# AS32x601 register map
File version: 1.0
CPU: RISC-V, little endian
Registers are 32-bit, read-write, reset 0x0 unless marked. A register's access mark holds for its fields unless they carry their own. Offsets are from the block's base; [hi:lo] are bit positions; {n}, {i} and the like mark numbered series.

## SMU — System Management Unit
Base 0x30006000
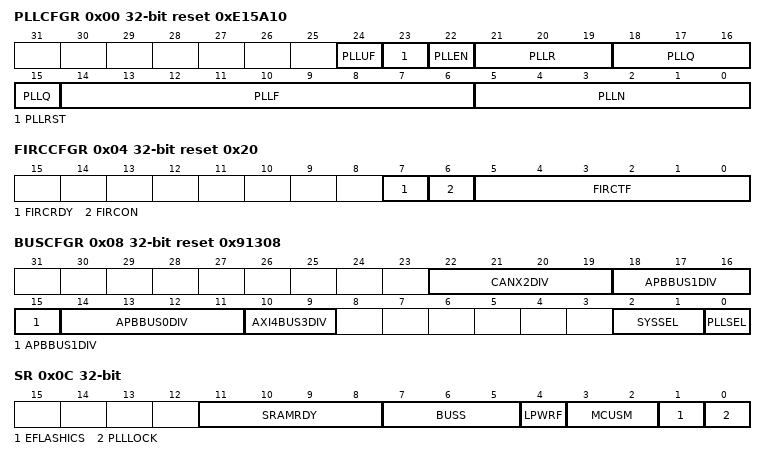
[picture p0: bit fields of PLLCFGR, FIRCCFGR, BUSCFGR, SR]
0x00 PLLCFGR reset 0xE15A10 — PLL divide and reset configuration registers
  [24] PLLUF — Update PLL frequency enable
  [23] PLLRST — PLL clock reset signal
  [22] PLLEN — PLL clock enable
  [21:19] PLLR — Output frequency division control signal of CLK_R [2:0]
  [18:15] PLLQ — Output frequency division control signal of CLK_Q [3:0]
  [14:6] PLLF — Feedback clock control signal [8:0]
  [5:0] PLLN — Input frequency division control signal [5:0]
0x04 FIRCCFGR reset 0x20 — Internal clock and reset configuration registers
  [7] FIRCRDY — FIRC oscillator preparation position
  [6] FIRCON — FIRC oscillator switch
  [5:0] FIRCTF — FIRC oscillator frequency adjustment [5:0]
0x08 BUSCFGR reset 0x91308 — BUS clock and reset configuration registers
  [22:19] CANX2DIV — CANX2 clock division ratio [3:0]
  [18:15] APBBUS1DIV — ApbBus1 clock division ratio [3:0]
  [14:11] APBBUS0DIV — ApbBus0 clock division ratio [3:0]
  [10:9] AXI4BUS3DIV — Axi4Bus3 clock division ratio [1:0]
  [2:1] SYSSEL — System clock selection [1:0]
  [0] PLLSEL — PLL clock selection
0x0C SR ro — SMU state registers
  [11:8] SRAMRDY — SRAM ready [3:0]
  [7:5] BUSS — Bus state [2:0]
  [4] LPWRF — Low power mode flag
  [3:2] MCUSM — MCU startup mode [1:0]
  [1] EFLASHICS — EFLASH initialization completion signal
  [0] PLLLOCK — PLL clock lock
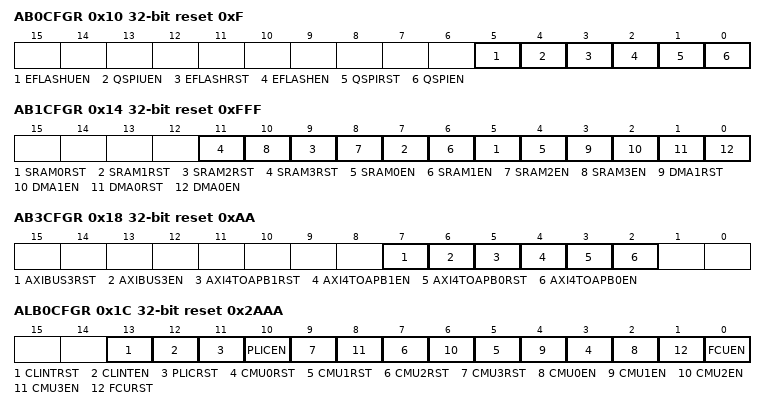
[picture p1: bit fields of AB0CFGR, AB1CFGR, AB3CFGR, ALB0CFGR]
0x10 AB0CFGR reset 0xF — AB0 bus clock and reset configuration register
  [5] EFLASHUEN — EFLASH clock update enable
  [4] QSPIUEN — QSPI Clock update Enable
  [3] EFLASHRST — EFLASH reset
  [2] EFLASHEN — EFLASH clock enable
  [1] QSPIRST — QSPI reset
  [0] QSPIEN — QSPI clock enable
0x14 AB1CFGR reset 0xFFF — AB1 bus clock and reset configuration register
  [2n+5] SRAM{n}RST (n=0..3) — SRAM{n} reset
  [2n+4] SRAM{n}EN (n=0..3) — SRAM{n} clock enable
  [3] DMA1RST — DMA1 reset
  [2] DMA1EN — DMA1 clock enable
  [1] DMA0RST — DMA0 reset
  [0] DMA0EN — DMA0 clock enable
0x18 AB3CFGR reset 0xAA — AB3 bus clock and reset configuration registers
  [7] AXIBUS3RST — AxiBux3 reset
  [6] AXIBUS3EN — AxiBux3 clock enable
  [5] AXI4TOAPB1RST — AXI4 to APB1 reset
  [4] AXI4TOAPB1EN — AXI4 to APB1 clock enable
  [3] AXI4TOAPB0RST — AXI4 to APB0 reset
  [2] AXI4TOAPB0EN — AXI4 to APB0 clock enable
0x1C ALB0CFGR reset 0x2AAA — ALB0 bus clock and reset configuration registers
  [13] CLINTRST — CLINT reset
  [12] CLINTEN — CLINT clock enable
  [11] PLICRST — PLIC reset
  [10] PLICEN — PLIC clock enable
  [2n+3] CMU{n}RST (n=0..3) — CMU{n} reset
  [2n+2] CMU{n}EN (n=0..3) — CMU{n} clock enable
  [1] FCURST — FCU reset
  [0] FCUEN — FCU clock enable
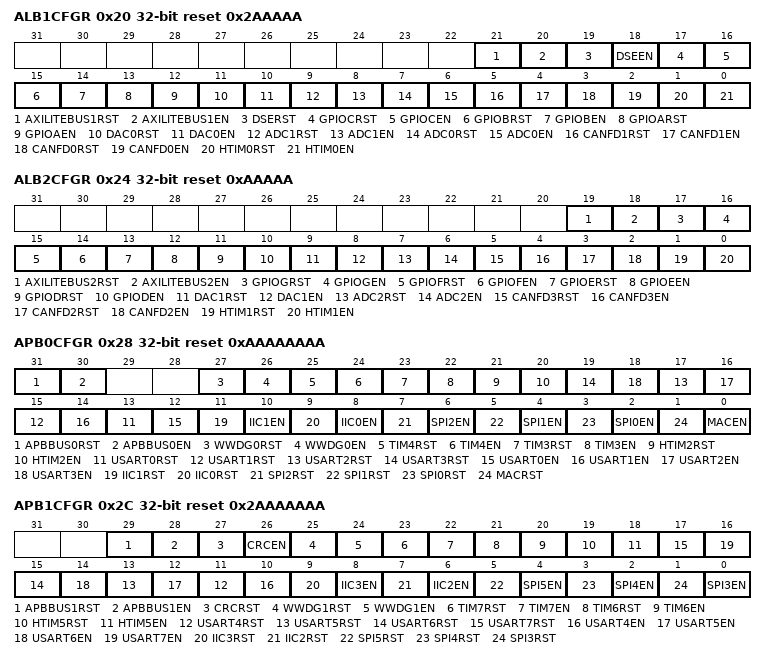
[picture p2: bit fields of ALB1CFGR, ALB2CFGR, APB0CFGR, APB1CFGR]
0x20 ALB1CFGR reset 0x2AAAAA — ALB1 bus clock and reset configuration registers
  [21] AXILITEBUS1RST — AXILiteBUS1 reset
  [20] AXILITEBUS1EN — AXILiteBUS1 clock enable
  [19] DSERST — DSE reset
  [18] DSEEN — DSE clock enable
  [17] GPIOCRST — GPIOC reset
  [16] GPIOCEN — GPIOC clock enable
  [15] GPIOBRST — GPIOB reset
  [14] GPIOBEN — GPIOB clock enable
  [13] GPIOARST — GPIOA reset
  [12] GPIOAEN — GPIOA clock enable
  [11] DAC0RST — DAC0 reset
  [10] DAC0EN — DAC0 clock enable
  [9] ADC1RST — ADC1 reset
  [8] ADC1EN — ADC1 clock enable
  [7] ADC0RST — ADC0 reset
  [6] ADC0EN — ADC0 clock enable
  [5] CANFD1RST — CANFD1 reset
  [4] CANFD1EN — CANFD1 clock enable
  [3] CANFD0RST — CANFD0 reset
  [2] CANFD0EN — CANFD0 clock enable
  [1] HTIM0RST — HTIM0 reset
  [0] HTIM0EN — HTIM0 clock enable
0x24 ALB2CFGR reset 0xAAAAA — ALB2 bus clock and reset configuration registers
  [19] AXILITEBUS2RST — AXILite Bus2 reset
  [18] AXILITEBUS2EN — AXILite Bus2 clock enable
  [17] GPIOGRST — GPIOG reset
  [16] GPIOGEN — GPIOG clock enable
  [15] GPIOFRST — GPIOF reset
  [14] GPIOFEN — GPIOF clock enable
  [13] GPIOERST — GPIOE reset
  [12] GPIOEEN — GPIOE clock enable
  [11] GPIODRST — GPIOD reset
  [10] GPIODEN — GPIOD clock enable
  [9] DAC1RST — DAC1 reset
  [8] DAC1EN — DAC1 clock enable
  [7] ADC2RST — ADC2 reset
  [6] ADC2EN — ADC2 clock enable
  [5] CANFD3RST — CANFD3 reset
  [4] CANFD3EN — CANFD3 clock enable
  [3] CANFD2RST — CANFD2 reset
  [2] CANFD2EN — CANFD2 clock enable
  [1] HTIM1RST — HTIM1 reset
  [0] HTIM1EN — HTIM1 clock enable
0x28 APB0CFGR reset 0xAAAAAAAA — APB0 bus clock and reset configuration registers
  [31] APBBUS0RST — APBBUS0 reset
  [30] APBBUS0EN — APBBUS0 clock enable
  [27] WWDG0RST — WWDG0 reset
  [26] WWDG0EN — WWDG0 clock enable
  [25] TIM4RST — TIM4 reset
  [24] TIM4EN — TIM4 clock enable
  [23] TIM3RST — TIM3 reset
  [22] TIM3EN — TIM3 clock enable
  [21] HTIM2RST — HTIM2 reset
  [20] HTIM2EN — HTIM2 clock enable
  [2n+13] USART{n}RST (n=0..3) — USART{n} reset
  [2n+12] USART{n}EN (n=0..3) — USART{n} clock enable
  [11] IIC1RST — IIC1 reset
  [10] IIC1EN — IIC1 clock enable
  [9] IIC0RST — IIC0 reset
  [8] IIC0EN — IIC0 clock enable
  [7] SPI2RST — SPI2 reset
  [6] SPI2EN — SPI2 clock enable
  [5] SPI1RST — SPI1 reset
  [4] SPI1EN — SPI1 clock enable
  [3] SPI0RST — SPI0 reset
  [2] SPI0EN — SPI0 clock enable
  [1] MACRST — MAC reset
  [0] MACEN — MAC clock enable
0x2C APB1CFGR reset 0x2AAAAAAA — APB1 bus clock and reset configuration registers
  [29] APBBUS1RST — APB1BUS1 reset
  [28] APBBUS1EN — APB1BUS1 clock enable
  [27] CRCRST — CRC reset
  [26] CRCEN — CRC clock enable
  [25] WWDG1RST — WWDG1 reset
  [24] WWDG1EN — WWDG1 clock enable
  [23] TIM7RST — TIM7 reset
  [22] TIM7EN — TIM7 clock enable
  [21] TIM6RST — TIM6 reset
  [20] TIM6EN — TIM6 clock enable
  [19] HTIM5RST — HTIM5 reset
  [18] HTIM5EN — HTIM5 clock enable
  [2n+3] USART{n}RST (n=4..7) — USART{n} reset
  [2n+2] USART{n}EN (n=4..7) — USART{n} clock enable
  [9] IIC3RST — IIC3 reset
  [8] IIC3EN — IIC3 clock enable
  [7] IIC2RST — IIC2 reset
  [6] IIC2EN — IIC2 clock enable
  [5] SPI5RST — SPI5 reset
  [4] SPI5EN — SPI5 clock enable
  [3] SPI4RST — SPI4 reset
  [2] SPI4EN — SPI4 clock enable
  [1] SPI3RST — SPI3 reset
  [0] SPI3EN — SPI3 clock enable
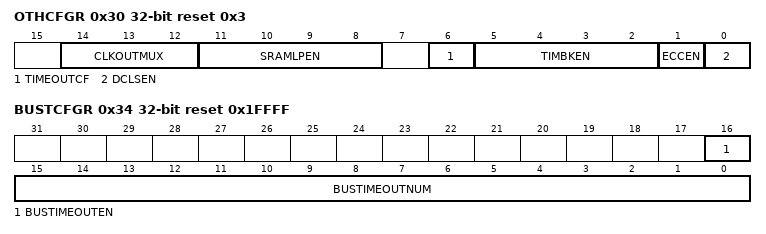
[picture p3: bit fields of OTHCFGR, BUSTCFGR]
0x30 OTHCFGR reset 0x3 — Other modules configuration registers
  [14:12] CLKOUTMUX — Clock Output Mux Select [2:0]
  [11:8] SRAMLPEN — SRAM Low Power Enable Signal [3:0]
  [6] TIMEOUTCF — Clear timeout flag
  [5:2] TIMBKEN — Advanced Timer Brake Enable [3:0]
  [1] ECCEN — ECC enable
  [0] DCLSEN — Dual core enable
0x34 BUSTCFGR reset 0x1FFFF — BUS timeout configuration registers
  [16] BUSTIMEOUTEN — Bus Timeout Enable
  [15:0] BUSTIMEOUTNUM — Bus Timeout Counter [15:0]
